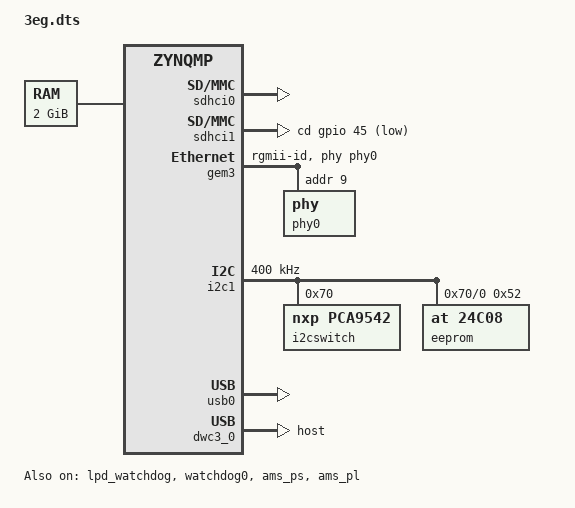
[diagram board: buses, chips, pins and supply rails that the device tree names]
/*
 * CAUTION: This file is automatically generated by Xilinx.
 * Version: XSCT 2018.3
 * Today is: Fri May 10 09:09:40 2019
 */


/dts-v1/;
#include "zynqmp.dtsi"
#include "zynqmp-clk-ccf.dtsi"
#include "pl.dtsi"
#include "pcw.dtsi"
/ {
	chosen {
		bootargs = "console=/dev/ttyPS0,115200 root=/dev/mmcblk1p2 rw earlyprintk earlycon clk_ignore_unused rootwait";
		stdout-path = "serial0:115200n8";
	};
	aliases {
		ethernet0 = &gem3;
		i2c0 = &i2c1;
		serial0 = &uart0;
		serial1 = &uart1;
		usb0 = &usb0;
	};
	memory {
		device_type = "memory";
		reg = <0x0 0x0 0x0 0x7ff00000>;
	};
};
&sdhci0 {
	clock-frequency = <199998001>;
	status = "okay";
	xlnx,mio_bank = <0x0>;
	nvmem-cells = <&soc_revision>;
	nvmem-cell-names = "soc_revision";
	#clock-cells = <1>;
	clock-output-names = "clk_out_sd0", "clk_in_sd0";
};

/* SD1 with level shifter */
&sdhci1 {
	status = "okay";
	cd-gpios = <&gpio 45 1>;	// cd-gpios = <&gpio 45 GPIO_ACTIVE_LOW>;
	cd-debounce-delay-ms = <500>;
   	max-frequency = <50000000>;
	no-1-8-v;	/* for 1.0 silicon */
};
    
&gem3 {
	status = "okay";
	local-mac-address = [00 0a 35 00 02 90];
	phy-mode = "rgmii-id";
	phy-handle = <&phy0>;
	phy0: phy@9 {
		reg = <0x9>;
		ti,rx-internal-delay = <0x5>;
		ti,tx-internal-delay = <0x5>;
		ti,fifo-depth = <0x1>;
	};
};

/*    
&spi0 {
    is-decoded-cs = <0>;
    num-cs = <1>;
	status = "okay";
    spidev@0x00 {
    compatible = "rohm,dh2228fv";
        spi-max-frequency = <50000000>;
        reg = <0>;
    };
};
*/
        
&i2c1 {
	status = "okay";
	clock-frequency = <400000>;

	i2cswitch@70 { /* U7 on UZ3EG SOM */
		compatible = "nxp,pca9542";
		#address-cells = <1>;
		#size-cells = <0>;
		reg = <0x70>;
		i2c@0 { /* i2c mw 70 0 1 */
			#address-cells = <1>;
			#size-cells = <0>;
			reg = <0>;
			/* IIC_EEPROM */
			eeprom@52 { /* U5 on UZ3EG IO Carrier*/
				compatible = "at,24c08";
				reg = <0x52>;
			};
		};
	};
};
/*
&amba_pl {
	mlscif_common: mlscif_common@80000000 {
	   compatible = "mlscif_common-1.0";
	   reg = <0x0 0x80000000 0x0 0x10000>;
    };
	mlscif_channel: mlscif_channel@80020000 {
	   compatible = "mlscif_channel-1.0";
	   reg = <0x0 0x80020000 0x0 0x10000>;
    };
	mlscif_selector: mlscif_selector@80200000 {
	   compatible = "mlscif_selector-1.0";
	   reg = <0x0 0x80200000 0x0 0x10000>;
    };
	gpreg_0: gpreg@80310000 {
		clock-names = "axi_lite_aclk";
		clocks = <&misc_clk_0>;
		compatible = "xlnx,gpreg-1.0";
		reg = <0x0 0x80310000 0x0 0x10000>;
		xlnx,axi-lite-addr-width = <0x6>;
		xlnx,axi-lite-data-width = <0x20>;
	};
	bssaif_common: bssaif_common@80010000 {
	   compatible = "bssaif_common-1.0";
	   reg = <0x0 0x80010000 0x0 0x10000>;
    };
	bssaif_src1: bssaif_src@81010000 {
	   compatible = "bssaif_src-1.0";
	   reg = <0x0 0x81010000 0x0 0x10000>;
    };
	bssaif_src2: bssaif_src@81020000 {
	   compatible = "bssaif_src-1.0";
	   reg = <0x0 0x81020000 0x0 0x10000>;
    };
	bssaif_src3: bssaif_src@81030000 {
	   compatible = "bssaif_src-1.0";
	   reg = <0x0 0x81030000 0x0 0x10000>;
    };
	bssaif_src4: bssaif_src@81040000 {
	   compatible = "bssaif_src-1.0";
	   reg = <0x0 0x81040000 0x0 0x10000>;
    };
	bssaif_src5: bssaif_src@81050000 {
	   compatible = "bssaif_src-1.0";
	   reg = <0x0 0x81050000 0x0 0x10000>;
    };
	bssaif_src6: bssaif_src@81060000 {
	   compatible = "bssaif_src-1.0";
	   reg = <0x0 0x81060000 0x0 0x10000>;
    };
	bssaif_src7: bssaif_src@81070000 {
	   compatible = "bssaif_src-1.0";
	   reg = <0x0 0x81070000 0x0 0x10000>;
    };
	bssaif_src8: bssaif_src@81080000 {
	   compatible = "bssaif_src-1.0";
	   reg = <0x0 0x81080000 0x0 0x10000>;
    };
	bssaif_src9: bssaif_src@81090000 {
	   compatible = "bssaif_src-1.0";
	   reg = <0x0 0x81090000 0x0 0x10000>;
    };
	bssaif_src10: bssaif_src@810a0000 {
	   compatible = "bssaif_src-1.0";
	   reg = <0x0 0x810a0000 0x0 0x10000>;
    };
	bssaif_src11: bssaif_src@810b0000 {
	   compatible = "bssaif_src-1.0";
	   reg = <0x0 0x810b0000 0x0 0x10000>;
    };
	bssaif_src12: bssaif_src@810c0000 {
	   compatible = "bssaif_src-1.0";
	   reg = <0x0 0x810c0000 0x0 0x10000>;
    };
	misc_clk_0: misc_clk_0 {
		#clock-cells = <0>;
		clock-frequency = <299997000>;
		compatible = "fixed-clock";
	};
};
*/
        
/* ULPI SMSC USB3320 */
&usb0 {
	status = "okay";
};

&dwc3_0 {
	status = "okay";
	dr_mode = "host";
	phy-names = "usb3-phy";
};
&lpd_watchdog {
	status = "okay";
};
&watchdog0 {
	status = "okay";
};
&ams_ps {
	status = "okay";
};
&ams_pl {
	status = "okay";
};
